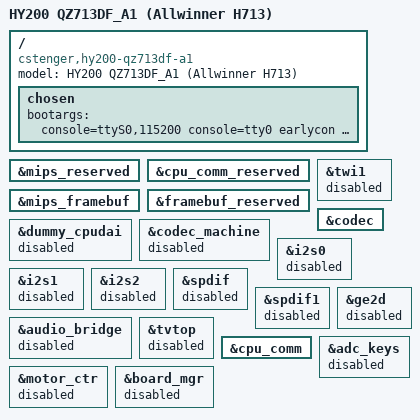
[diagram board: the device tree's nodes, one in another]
/dts-v1/;

#include "sun50i-h713.dtsi"

/ {
	model = "HY200 QZ713DF_A1 (Allwinner H713)";
	compatible = "cstenger,hy200-qz713df-a1", "allwinner,sun50i-h713";

	chosen {
		bootargs = "console=ttyS0,115200 console=tty0 earlycon root=/dev/mmcblk0p26 rootwait rootfstype=ext4 rw net.ifnames=0 panic=5 clk_ignore_unused pd_ignore_unused cma=128M";
	};
};

&mips_reserved { status = "okay"; };
&cpu_comm_reserved { status = "okay"; };
&mips_framebuf { status = "okay"; };
&framebuf_reserved { status = "okay"; };
&twi1 { status = "disabled"; };
&codec { status = "okay"; };
&dummy_cpudai { status = "disabled"; };
&codec_machine { status = "disabled"; };
&i2s0 { status = "disabled"; };
&i2s1 { status = "disabled"; };
&i2s2 { status = "disabled"; };
&spdif { status = "disabled"; };
&spdif1 { status = "disabled"; };
&audio_bridge { status = "disabled"; };
&ge2d { status = "disabled"; };
&tvtop { status = "disabled"; };
/*
 * DECD enabled 2026-08-12 for zero-copy video: it is the only way to
 * hand the display a decoder buffer, since userspace can neither resolve
 * a V4L2 buffer to a physical address nor program display registers.
 * Built as a module so it is loaded deliberately, after U-Boot has set
 * up the panel. TVTOP stays disabled -- see patch 0033.
 */
&cpu_comm { status = "okay"; };	/* Treiber wird seit 01.09. gebaut */
&motor_ctr { status = "disabled"; };	/* Endschalter liefert nichts, siehe doku/94 */
&adc_keys { status = "disabled"; };
&board_mgr { status = "disabled"; };
